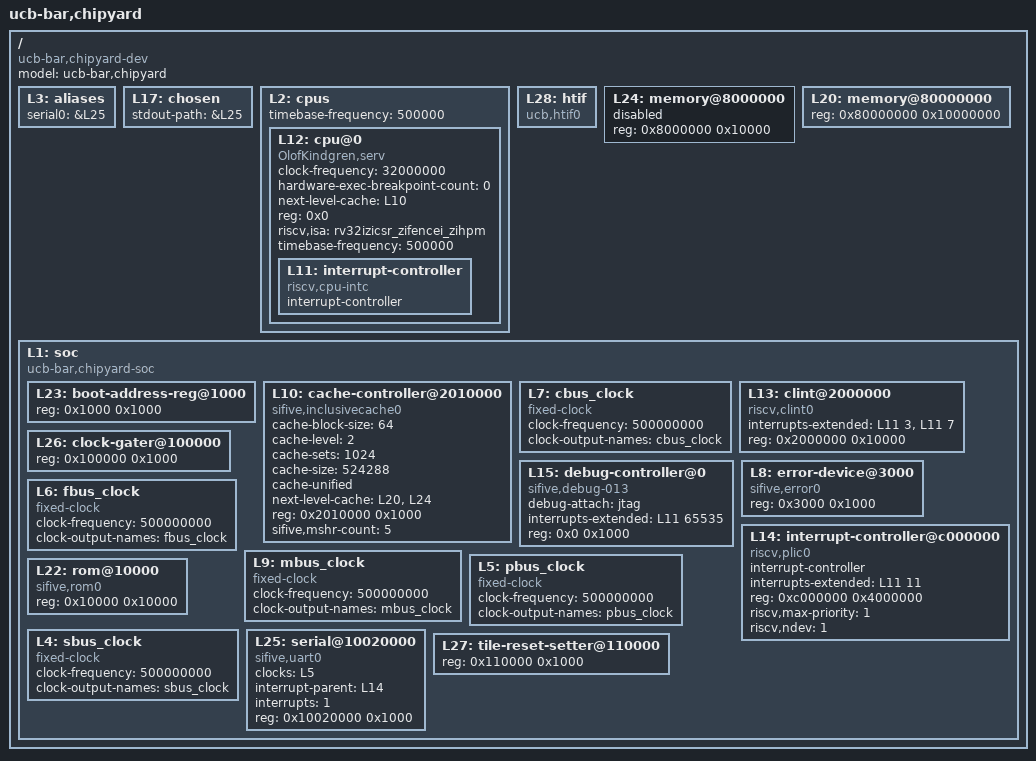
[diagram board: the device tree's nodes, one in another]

/dts-v1/;

/ {
	#address-cells = <1>;
	#size-cells = <1>;
	compatible = "ucb-bar,chipyard-dev";
	model = "ucb-bar,chipyard";
	L3: aliases {
		serial0 = &L25;
	};
	L17: chosen {
		stdout-path = &L25;
	};
	L2: cpus {
		#address-cells = <1>;
		#size-cells = <0>;
		timebase-frequency = <500000>;
		L12: cpu@0 {
			clock-frequency = <32000000>;
			compatible = "OlofKindgren,serv", "riscv";
			device_type = "cpu";
			hardware-exec-breakpoint-count = <0>;
			next-level-cache = <&L10>;
			reg = <0x0>;
			riscv,isa = "rv32izicsr_zifencei_zihpm";
			status = "okay";
			timebase-frequency = <500000>;
			L11: interrupt-controller {
				#interrupt-cells = <1>;
				compatible = "riscv,cpu-intc";
				interrupt-controller;
			};
		};
	};
	L28: htif {
		compatible = "ucb,htif0";
	};
	L24: memory@8000000 {
		device_type = "memory";
		reg = <0x8000000 0x10000>;
		status = "disabled";
	};
	L20: memory@80000000 {
		device_type = "memory";
		reg = <0x80000000 0x10000000>;
	};
	L1: soc {
		#address-cells = <1>;
		#size-cells = <1>;
		compatible = "ucb-bar,chipyard-soc", "simple-bus";
		ranges;
		L23: boot-address-reg@1000 {
			reg = <0x1000 0x1000>;
			reg-names = "control";
		};
		L10: cache-controller@2010000 {
			cache-block-size = <64>;
			cache-level = <2>;
			cache-sets = <1024>;
			cache-size = <524288>;
			cache-unified;
			compatible = "sifive,inclusivecache0", "cache";
			next-level-cache = <&L20 &L24>;
			reg = <0x2010000 0x1000>;
			reg-names = "control";
			sifive,mshr-count = <5>;
		};
		L7: cbus_clock {
			#clock-cells = <0>;
			clock-frequency = <500000000>;
			clock-output-names = "cbus_clock";
			compatible = "fixed-clock";
		};
		L13: clint@2000000 {
			compatible = "riscv,clint0";
			interrupts-extended = <&L11 3 &L11 7>;
			reg = <0x2000000 0x10000>;
			reg-names = "control";
		};
		L26: clock-gater@100000 {
			reg = <0x100000 0x1000>;
			reg-names = "control";
		};
		L15: debug-controller@0 {
			compatible = "sifive,debug-013", "riscv,debug-013";
			debug-attach = "jtag";
			interrupts-extended = <&L11 65535>;
			reg = <0x0 0x1000>;
			reg-names = "control";
		};
		L8: error-device@3000 {
			compatible = "sifive,error0";
			reg = <0x3000 0x1000>;
		};
		L6: fbus_clock {
			#clock-cells = <0>;
			clock-frequency = <500000000>;
			clock-output-names = "fbus_clock";
			compatible = "fixed-clock";
		};
		L14: interrupt-controller@c000000 {
			#interrupt-cells = <1>;
			compatible = "riscv,plic0";
			interrupt-controller;
			interrupts-extended = <&L11 11>;
			reg = <0xc000000 0x4000000>;
			reg-names = "control";
			riscv,max-priority = <1>;
			riscv,ndev = <1>;
		};
		L9: mbus_clock {
			#clock-cells = <0>;
			clock-frequency = <500000000>;
			clock-output-names = "mbus_clock";
			compatible = "fixed-clock";
		};
		L5: pbus_clock {
			#clock-cells = <0>;
			clock-frequency = <500000000>;
			clock-output-names = "pbus_clock";
			compatible = "fixed-clock";
		};
		L22: rom@10000 {
			compatible = "sifive,rom0";
			reg = <0x10000 0x10000>;
			reg-names = "mem";
		};
		L4: sbus_clock {
			#clock-cells = <0>;
			clock-frequency = <500000000>;
			clock-output-names = "sbus_clock";
			compatible = "fixed-clock";
		};
		L25: serial@10020000 {
			clocks = <&L5>;
			compatible = "sifive,uart0";
			interrupt-parent = <&L14>;
			interrupts = <1>;
			reg = <0x10020000 0x1000>;
			reg-names = "control";
		};
		L27: tile-reset-setter@110000 {
			reg = <0x110000 0x1000>;
			reg-names = "control";
		};
	};
};
